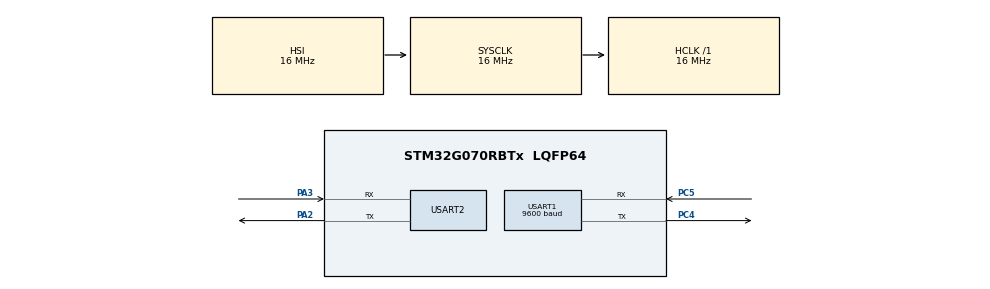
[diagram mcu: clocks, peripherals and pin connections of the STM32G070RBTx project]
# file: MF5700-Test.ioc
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Dma.Request0=USART1_RX
Dma.Request1=USART1_TX
Dma.USART1_RX.0.Direction=DMA_PERIPH_TO_MEMORY
Dma.USART1_RX.0.EventEnable=DISABLE
Dma.USART1_RX.0.Instance=DMA1_Channel1
Dma.USART1_RX.0.MemDataAlignment=DMA_MDATAALIGN_BYTE
Dma.USART1_RX.0.MemInc=DMA_MINC_ENABLE
Dma.USART1_RX.0.Mode=DMA_NORMAL
Dma.USART1_RX.0.PeriphDataAlignment=DMA_PDATAALIGN_BYTE
Dma.USART1_RX.0.PeriphInc=DMA_PINC_DISABLE
Dma.USART1_RX.0.Polarity=HAL_DMAMUX_REQ_GEN_RISING
Dma.USART1_RX.0.Priority=DMA_PRIORITY_LOW
Dma.USART1_RX.0.RequestNumber=1
Dma.USART1_RX.0.SignalID=NONE
Dma.USART1_RX.0.SyncEnable=DISABLE
Dma.USART1_RX.0.SyncPolarity=HAL_DMAMUX_SYNC_NO_EVENT
Dma.USART1_RX.0.SyncRequestNumber=1
Dma.USART1_RX.0.SyncSignalID=NONE
Dma.USART1_TX.1.Direction=DMA_MEMORY_TO_PERIPH
Dma.USART1_TX.1.EventEnable=DISABLE
Dma.USART1_TX.1.Instance=DMA1_Channel2
Dma.USART1_TX.1.MemDataAlignment=DMA_MDATAALIGN_BYTE
Dma.USART1_TX.1.MemInc=DMA_MINC_ENABLE
Dma.USART1_TX.1.Mode=DMA_NORMAL
Dma.USART1_TX.1.PeriphDataAlignment=DMA_PDATAALIGN_BYTE
Dma.USART1_TX.1.PeriphInc=DMA_PINC_DISABLE
Dma.USART1_TX.1.Polarity=HAL_DMAMUX_REQ_GEN_RISING
Dma.USART1_TX.1.Priority=DMA_PRIORITY_LOW
Dma.USART1_TX.1.RequestNumber=1
Dma.USART1_TX.1.SignalID=NONE
Dma.USART1_TX.1.SyncEnable=DISABLE
Dma.USART1_TX.1.SyncPolarity=HAL_DMAMUX_SYNC_NO_EVENT
Dma.USART1_TX.1.SyncRequestNumber=1
Dma.USART1_TX.1.SyncSignalID=NONE
Mcu.Family=STM32G0
Mcu.Name=STM32G070RBTx
Mcu.Package=LQFP64
NVIC.DMA1_Channel1_IRQn=true\:0\:0\:false\:false\:true\:false\:true\:true
NVIC.DMA1_Channel2_3_IRQn=true\:0\:0\:false\:false\:true\:false\:true\:true
NVIC.USART1_IRQn=true\:0\:0\:false\:false\:true\:true\:true\:true
PA13.Mode=Serial_Wire
PA13.Signal=SYS_SWDIO
PA14-BOOT0.Mode=Serial_Wire
PA14-BOOT0.Signal=SYS_SWCLK
PA2.Mode=Asynchronous
PA2.Signal=USART2_TX
PA3.Mode=Asynchronous
PA3.Signal=USART2_RX
PC4.Mode=Asynchronous
PC4.Signal=USART1_TX
PC5.Mode=Asynchronous
PC5.Signal=USART1_RX
ProjectManager.HeapSize=0x200
ProjectManager.StackSize=0x400
ProjectManager.TargetToolchain=STM32CubeIDE
RCC.AHBFreq_Value=16000000
RCC.CortexFreq_Value=16000000
RCC.EXTERNAL_CLOCK_VALUE=48000
RCC.HCLKFreq_Value=16000000
RCC.HSE_VALUE=8000000
RCC.HSI_VALUE=16000000
RCC.LSE_VALUE=32768
RCC.SYSCLKFreq_VALUE=16000000
RCC.VCOOutputFreq_Value=128000000
USART1.BaudRate=9600
USART1.VirtualMode-Asynchronous=VM_ASYNC
USART2.VirtualMode-Asynchronous=VM_ASYNC
VP_SYS_VS_DBSignals.Mode=DisableDeadBatterySignals
board=custom

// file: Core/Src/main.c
/* USER CODE BEGIN Header */
/**
  ******************************************************************************
  * @file           : main.c
  * @brief          : Main program body
  ******************************************************************************
  * @attention
  *
  * Copyright (c) 2023 STMicroelectronics.
  * All rights reserved.
  *
  * This software is licensed under terms that can be found in the LICENSE file
  * in the root directory of this software component.
  * If no LICENSE file comes with this software, it is provided AS-IS.
  *
  ******************************************************************************
  */
/* USER CODE END Header */
#include "main.h"
#include "dma.h"
#include "usart.h"
#include "gpio.h"

/* USER CODE BEGIN Includes */
#include "rs485_usart1.h"
/* USER CODE END Includes */

void SystemClock_Config(void);
/* USER CODE BEGIN PFP */
void Util_Receive_IT(UART_HandleTypeDef *huart);
/* USER CODE END PFP */

int main(void)
{

  /* MCU Configuration--------------------------------------------------------*/

  /* Reset of all peripherals, Initializes the Flash interface and the Systick. */
  HAL_Init();

  /* Configure the system clock */
  SystemClock_Config();

  /* Initialize all configured peripherals */
  MX_GPIO_Init();
  MX_DMA_Init();
  MX_USART1_UART_Init();
  MX_USART2_UART_Init();
  /* USER CODE BEGIN 2 */
  __HAL_UART_ENABLE_IT(&huart1,UART_IT_IDLE);  //使能空闲中断
  HAL_UART_Receive_DMA(&huart1,pRS485RxBuff,RS485_MAXSIZE);  //启动DMA接收，UART1_RX_BUF：数据接收缓冲
  close_write_FF();
  /* USER CODE END 2 */

  /* Infinite loop */
  while (1)
  {
    read_flow();
    HAL_Delay(1000);
  }
}

void SystemClock_Config(void)
{
  RCC_OscInitTypeDef RCC_OscInitStruct = {0};
  RCC_ClkInitTypeDef RCC_ClkInitStruct = {0};

  /** Configure the main internal regulator output voltage
  */
  HAL_PWREx_ControlVoltageScaling(PWR_REGULATOR_VOLTAGE_SCALE1);

  /** Initializes the RCC Oscillators according to the specified parameters
  * in the RCC_OscInitTypeDef structure.
  */
  RCC_OscInitStruct.OscillatorType = RCC_OSCILLATORTYPE_HSI;
  RCC_OscInitStruct.HSIState = RCC_HSI_ON;
  RCC_OscInitStruct.HSIDiv = RCC_HSI_DIV1;
  RCC_OscInitStruct.HSICalibrationValue = RCC_HSICALIBRATION_DEFAULT;
  RCC_OscInitStruct.PLL.PLLState = RCC_PLL_NONE;
  if (HAL_RCC_OscConfig(&RCC_OscInitStruct) != HAL_OK)
  {
    Error_Handler();
  }

  /** Initializes the CPU, AHB and APB buses clocks
  */
  RCC_ClkInitStruct.ClockType = RCC_CLOCKTYPE_HCLK|RCC_CLOCKTYPE_SYSCLK
                              |RCC_CLOCKTYPE_PCLK1;
  RCC_ClkInitStruct.SYSCLKSource = RCC_SYSCLKSOURCE_HSI;
  RCC_ClkInitStruct.AHBCLKDivider = RCC_SYSCLK_DIV1;
  RCC_ClkInitStruct.APB1CLKDivider = RCC_HCLK_DIV1;

  if (HAL_RCC_ClockConfig(&RCC_ClkInitStruct, FLASH_LATENCY_0) != HAL_OK)
  {
    Error_Handler();
  }
}

void Error_Handler(void)
{
  __disable_irq();
  while (1)
  {
  }
}
